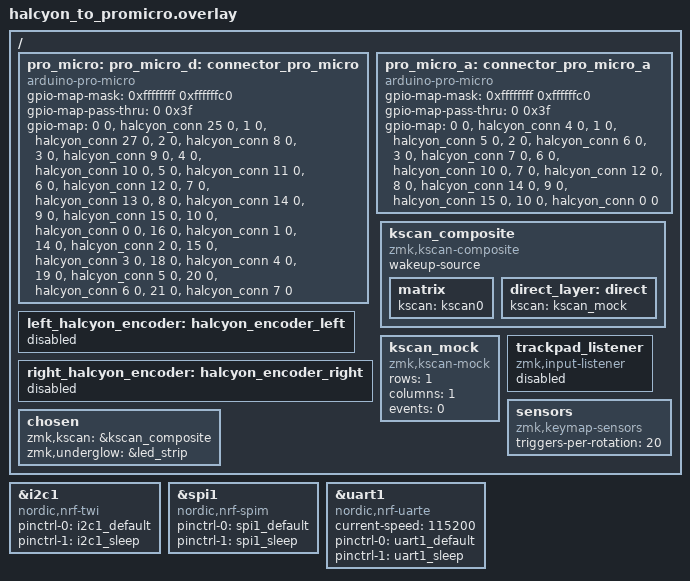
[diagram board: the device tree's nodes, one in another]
#include "vik_connector.dtsi"

/ {
    pro_micro: connector_pro_micro {
        compatible = "arduino-pro-micro";
        #gpio-cells = <2>;
        gpio-map-mask = <0xffffffff 0xffffffc0>;
        gpio-map-pass-thru = <0 0x3f>;
        gpio-map
            = <0 0 &halcyon_conn 25 0> /* D0 */
            , <1 0 &halcyon_conn 27 0> /* D1 */
            , <2 0 &halcyon_conn 8 0>  /* D2 */
            , <3 0 &halcyon_conn 9 0>  /* D3 */
            , <4 0 &halcyon_conn 10 0> /* D4/A6 */
            , <5 0 &halcyon_conn 11 0> /* D5 */
            , <6 0 &halcyon_conn 12 0> /* D6/A7 */
            , <7 0 &halcyon_conn 13 0> /* D7 */
            , <8 0 &halcyon_conn 14 0> /* D8/A8 */
            , <9 0 &halcyon_conn 15 0> /* D9/A9 */
            , <10 0 &halcyon_conn 0 0> /* D10/A10 */
            , <16 0 &halcyon_conn 1 0> /* D16 */
            , <14 0 &halcyon_conn 2 0> /* D14 */
            , <15 0 &halcyon_conn 3 0> /* D15 */
            , <18 0 &halcyon_conn 4 0> /* D18/A0 */
            , <19 0 &halcyon_conn 5 0> /* D19/A1 */
            , <20 0 &halcyon_conn 6 0> /* D20/A2 */
            , <21 0 &halcyon_conn 7 0> /* D21/A3 */
            ;
    };

    pro_micro_a: connector_pro_micro_a {
        compatible = "arduino-pro-micro";
        #gpio-cells = <2>;
        gpio-map-mask = <0xffffffff 0xffffffc0>;
        gpio-map-pass-thru = <0 0x3f>;
        gpio-map
            = <0 0 &halcyon_conn 4 0>  /* D18/A0 */
            , <1 0 &halcyon_conn 5 0>  /* D19/A1 */
            , <2 0 &halcyon_conn 6 0>  /* D20/A2 */
            , <3 0 &halcyon_conn 7 0>  /* D21/A3 */
            , <6 0 &halcyon_conn 10 0> /* D4/A6 */
            , <7 0 &halcyon_conn 12 0> /* D6/A7 */
            , <8 0 &halcyon_conn 14 0> /* D8/A8 */
            , <9 0 &halcyon_conn 15 0> /* D9/A9 */
            , <10 0 &halcyon_conn 0 0> /* D10/A10 */
            ;
    };

    left_halcyon_encoder: halcyon_encoder_left {
        status = "disabled";
    };

    right_halcyon_encoder: halcyon_encoder_right {
        status = "disabled";
    };

    kscan_composite: kscan_composite {
        compatible = "zmk,kscan-composite";
        wakeup-source;

        matrix {
            kscan = <&kscan0>;
        };

        direct_layer: direct {
            kscan = <&kscan_mock>;
        };
    };

    kscan_mock: kscan_mock {
        compatible = "zmk,kscan-mock";
        rows = <1>;
        columns = <1>;
        events = <0>;
    };

    chosen {
        zmk,kscan = &kscan_composite;
        zmk,underglow = &led_strip;
    };

    trackpad_listener: trackpad_listener {
        compatible = "zmk,input-listener";
        status = "disabled";
    };

    sensors: sensors {
        compatible = "zmk,keymap-sensors";
        triggers-per-rotation = <20>;
    };

    
};

&i2c1 {
    compatible = "nordic,nrf-twi";
    pinctrl-0 = <&i2c1_default>;
    pinctrl-1 = <&i2c1_sleep>;
    pinctrl-names = "default", "sleep";
};

&spi1 {
    compatible = "nordic,nrf-spim";
    pinctrl-0 = <&spi1_default>;
    pinctrl-1 = <&spi1_sleep>;
    pinctrl-names = "default", "sleep";
};

&uart1 {
    compatible = "nordic,nrf-uarte";
    current-speed = <115200>;
    pinctrl-0 = <&uart1_default>;
    pinctrl-1 = <&uart1_sleep>;
    pinctrl-names = "default", "sleep";
};

pro_micro_d: &pro_micro {};
pro_micro_i2c: &i2c1 {};
pro_micro_spi: &spi1 {};
pro_micro_serial: &uart1 {};
